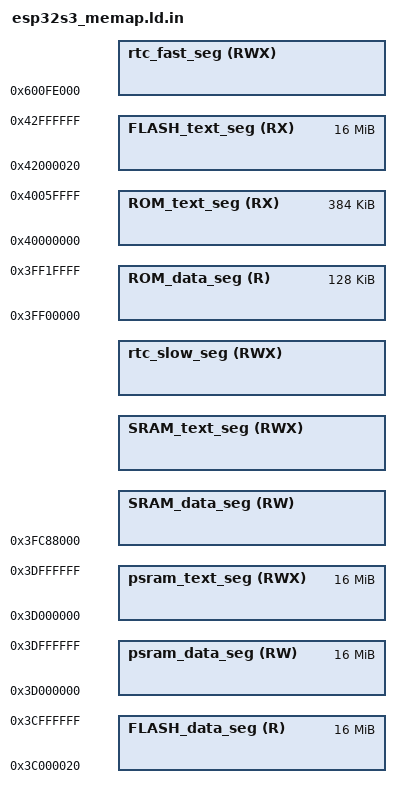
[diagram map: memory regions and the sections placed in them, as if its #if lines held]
/*
    SRAM mapping
        ref: 4.3.2, table 4-1

        +--------+-----------------...---------------+----------------+
        | 32K    | 416K data/instruction shared      | 64K            |
        +--------+-----------------...---------------+----------------+
        ^        ^                                   ^
        SRAM0    SRAM1                               SRAM2
        cache/data ================>
                                   <================ instruction/cache

    .SRAM0
        0x40370000 => ICACHE, configuratable 16k/32K

    .SRAM1
        ... 16/32K
        416K 0x40378000 ~ 0x403E0000: instruction segment
            OFFSET = 0x6F0000
        416K 0x3FC88000 ~ 0x3FCF0000: data segment
        ... 16K/32K/64K

    .SRAM2
        0x3FCF0000  => DCACHE, configuratable 16k/32k/64k

    ADDR mapping
        0x40370000 => 32K ICACHE => 0x40378000 => 416K IRAM  => 0x403E0000
                                    0x3FC88000 => 416K DRAM  => 0x3FCF0000 => 64K DCACHE => 0x3FD00000
*/
#define SRAM_DIRAM_I_START              0x40378000
#define SRAM_IRAM_END                   0x403CC700 /* Please refer to ESP32-S3 bootloader.ld for more information on this */
#define I_D_SRAM_OFFSET                 (0x6F0000)

#define SRAM_DRAM_END                   (SRAM_IRAM_END - I_D_SRAM_OFFSET)  /* 2nd stage bootloader iram_loader_seg start address */
#define I_D_SRAM_SIZE                   (SRAM_DRAM_END - 0x3FC88000)


#define SRAM_IRAM_SIZE                  (I_D_SRAM_SIZE + ICACHE_SIZE - CONFIG_ESP32S3_INSTRUCTION_CACHE_SIZE)


#include "sdkconfig.h"
/*
    CONFIG_SOC_MEMPROT_CPU_PREFETCH_PAD_SIZE
        fixed = 16
*/
/*
    CONFIG_SOC_MEMPROT_MEM_ALIGN_SIZE
        fixed = 256
*/
;
/****************************************************************************
 * sdkconfig.h
*****************************************************************************/
#ifdef CONFIG_BOOTLOADER_CUSTOM_RESERVE_RTC
    #define ESP_BOOTLOADER_RESERVE_RTC  (CONFIG_BOOTLOADER_RESERVE_RTC_SIZE + CONFIG_BOOTLOADER_CUSTOM_RESERVE_RTC_SIZE)
#elif defined(CONFIG_BOOTLOADER_SKIP_VALIDATE_IN_DEEP_SLEEP)
    #define ESP_BOOTLOADER_RESERVE_RTC  (CONFIG_BOOTLOADER_RESERVE_RTC_SIZE)
#else
    #define ESP_BOOTLOADER_RESERVE_RTC  0
#endif

#if false
    # TODO: remove THIS

    #if CONFIG_ESP32S3_USE_FIXED_STATIC_RAM_SIZE
        ASSERT((CONFIG_ESP32S3_FIXED_STATIC_RAM_SIZE <= I_D_SRAM_SIZE), "Fixed static ram data does not fit.")
        #define DRAM0_0_SEG_LEN             CONFIG_ESP32S3_FIXED_STATIC_RAM_SIZE
    #else
        #define DRAM0_0_SEG_LEN             I_D_SRAM_SIZE
    #endif
#endif

    ICACHE_SIZE =                   CONFIG_ESP32S3_INSTRUCTION_CACHE_SIZE;
    DCACHE_SIZE =                   CONFIG_ESP32S3_DATA_CACHE_SIZE;

#ifdef CONFIG_ULP_COPROC_RESERVE_MEM
    ULP_RESERVED_RTC_SLOW_SIZE =    CONFIG_ULP_COPROC_RESERVE_MEM;
#else
    ULP_RESERVED_RTC_SLOW_SIZE =    0;
#endif
;
MEMORY
{
    /*
        internal ROM
    */
    ROM_data_seg (R) :              org = 0x3FF00000,   len = 128K  /* ESP system internal use, program able? */
    ROM_text_seg (RX) :             org = 0x40000000,   len = 384k  /* ESP system internal use, program able? */

    /*
        internal SRAM
    */
    SRAM_data_seg (RW) :            org = 0x3FC88000,   len = 480k - DCACHE_SIZE
    SRAM_text_seg (RWX) :           org = 0x40370000 + ICACHE_SIZE, len = 448K - ICACHE_SIZE

    /*
        RTC segments
    */
    rtc_slow_seg(RWX) :             org = 0x50000000 + ULP_RESERVED_RTC_SLOW_SIZE, len = 8K - ULP_RESERVED_RTC_SLOW_SIZE
    rtc_fast_seg(RWX) :             org = 0x600FE000,   len = 8K - ESP_BOOTLOADER_RESERVE_RTC

    /*
        external FLASH
    */
    FLASH_data_seg (R) :            org = 0x3C000020,   len = 16M - 0x20
    FLASH_text_seg (RX) :           org = 0x42000020,   len = 16M - 0x20

    /*
        PSRAM
    */
    psram_data_seg (RW) :           org = 0x3D000000,   len = 16M
    psram_text_seg (RWX) :          org = 0x3D000000,   len = 16M   /* exists PSRAM text? */
}
/*
    Memory Usage of ROM 1st bootloader

        0x3fcd7e00 ------------------> _dram0_0_start
                   |               |
                   |               |
                   |               |   1. Large buffers that are only used in certain boot modes, see shared_buffers.h
                   |               |
                   |               |
        0x3fce9710 ------------------> __stack_sentry
                   |               |
                   |               |   2. Startup pro cpu stack (freed when IDF app is running)
                   |               |
        0x3fceb710 ------------------> __stack (pro cpu)
                   |               |
                   |               |      Startup app cpu stack
                   |               |
        0x3fced710 ------------------> __stack_app (app cpu)
                   |               |
                   |               |
                   |               |   3. Shared memory only used in startup code or nonos/early boot*
                   |               |      (can be freed when IDF runs)
                   |               |
                   |               |
        0x3fceee34 ------------------> _dram0_rtos_reserved_start
                   |               |
                   |               |
                   |               |   4. Shared memory used in startup code and when IDF runs
                   |               |
                   |               |
        0x3fcef770 ------------------> _dram0_rtos_reserved_end
                   |               |
        0x3fcef81c ------------------> _data_start_interface
                   |               |
                   |               |   5. End of DRAM is the 'interface' data with constant addresses (ECO compatible)
                   |               |
        0x3fcf0000 ------------------> _data_end_interface
*/

/*
    MEMORY segment aliases
*/
#if false
    # TODO: remove CONFIG_APP_BUILD_USE_FLASH_SECTIONS
#endif
REGION_ALIAS("default_code_seg",    FLASH_text_seg);

#if CONFIG_APP_BUILD_USE_FLASH_SECTIONS
REGION_ALIAS("default_rodata_seg",  FLASH_data_seg);
#else
REGION_ALIAS("default_rodata_seg",  SRAM_data_seg);
#endif

REGION_ALIAS("rtc_iram_seg",        rtc_fast_seg);
#if CONFIG_ESP32S3_RTCDATA_IN_FAST_MEM
REGION_ALIAS("rtc_data_location",   rtc_fast_seg);
#else
REGION_ALIAS("rtc_data_location",   rtc_slow_seg);
#endif
